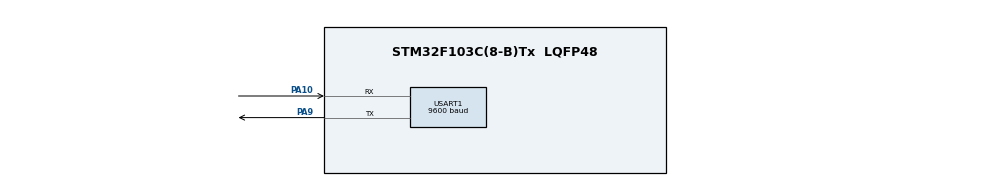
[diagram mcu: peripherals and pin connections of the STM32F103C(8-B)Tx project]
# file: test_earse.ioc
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Dma.Request0=USART1_RX
Dma.USART1_RX.0.Direction=DMA_PERIPH_TO_MEMORY
Dma.USART1_RX.0.Instance=DMA1_Channel5
Dma.USART1_RX.0.MemDataAlignment=DMA_MDATAALIGN_BYTE
Dma.USART1_RX.0.MemInc=DMA_MINC_ENABLE
Dma.USART1_RX.0.Mode=DMA_CIRCULAR
Dma.USART1_RX.0.PeriphDataAlignment=DMA_PDATAALIGN_BYTE
Dma.USART1_RX.0.PeriphInc=DMA_PINC_DISABLE
Dma.USART1_RX.0.Priority=DMA_PRIORITY_LOW
Mcu.Family=STM32F1
Mcu.Name=STM32F103C(8-B)Tx
Mcu.Package=LQFP48
NVIC.DMA1_Channel5_IRQn=true\:0\:0\:false\:false\:true\:false\:true
NVIC.PriorityGroup=NVIC_PRIORITYGROUP_4
PA10.Mode=Asynchronous
PA10.Signal=USART1_RX
PA13.Mode=Serial_Wire
PA13.Signal=SYS_JTMS-SWDIO
PA14.Mode=Serial_Wire
PA14.Signal=SYS_JTCK-SWCLK
PA9.Mode=Asynchronous
PA9.Signal=USART1_TX
ProjectManager.HeapSize=0x200
ProjectManager.StackSize=0x400
ProjectManager.TargetToolchain=STM32CubeIDE
RCC.APB1Freq_Value=8000000
RCC.APB2Freq_Value=8000000
USART1.BaudRate=9600
USART1.VirtualMode=VM_ASYNC
board=custom

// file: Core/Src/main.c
/* USER CODE BEGIN Header */
/**
 ******************************************************************************
 * @file           : main.c
 * @brief          : Main program body
 ******************************************************************************
 * @attention
 *
 * <h2><center>&copy; Copyright (c) 2021 STMicroelectronics.
 * All rights reserved.</center></h2>
 *
 * This software component is licensed by ST under BSD 3-Clause license,
 * the "License"; You may not use this file except in compliance with the
 * License. You may obtain a copy of the License at:
 *                        opensource.org/licenses/BSD-3-Clause
 *
 ******************************************************************************
 */
/* USER CODE END Header */
#include "main.h"

UART_HandleTypeDef huart1;
DMA_HandleTypeDef hdma_usart1_rx;

void SystemClock_Config(void);
static void MX_GPIO_Init(void);
static void MX_DMA_Init(void);
static void MX_USART1_UART_Init(void);

/* USER CODE BEGIN 0 */
void FlashErase(uint32_t address, uint8_t numSector)__attribute__((section(".run_in_ram")));
/* USER CODE END 0 */

int main(void)
{

  /* MCU Configuration--------------------------------------------------------*/

  /* Reset of all peripherals, Initializes the Flash interface and the Systick. */
  HAL_Init();

  /* Configure the system clock */
  SystemClock_Config();

  /* Initialize all configured peripherals */
  MX_GPIO_Init();
  MX_DMA_Init();
  MX_USART1_UART_Init();
  /* USER CODE BEGIN 2 */
	// COPY
	MY_EFROM_INIT();
	__HAL_RCC_USART1_CLK_ENABLE();
	__HAL_RCC_DMA1_CLK_ENABLE();
	HAL_UART_Init(&huart1);
	HAL_DMA_Init(&hdma_usart1_rx);

	//uint32_t *VTOR = 0xE000ED08;
	//*VTOR = 0x20000000;
	//memcpy(0x20000000, 0x08000000, 304);

  /* USER CODE END 2 */

  /* Infinite loop */
	while (1) {

    /* USER CODE BEGIN 3 */
		FlashErase(0x08000000,31);
		break;
	}
  /* USER CODE END 3 */
}

void SystemClock_Config(void)
{
  RCC_OscInitTypeDef RCC_OscInitStruct = {0};
  RCC_ClkInitTypeDef RCC_ClkInitStruct = {0};

  /** Initializes the RCC Oscillators according to the specified parameters
  * in the RCC_OscInitTypeDef structure.
  */
  RCC_OscInitStruct.OscillatorType = RCC_OSCILLATORTYPE_HSI;
  RCC_OscInitStruct.HSIState = RCC_HSI_ON;
  RCC_OscInitStruct.HSICalibrationValue = RCC_HSICALIBRATION_DEFAULT;
  RCC_OscInitStruct.PLL.PLLState = RCC_PLL_NONE;
  if (HAL_RCC_OscConfig(&RCC_OscInitStruct) != HAL_OK)
  {
    Error_Handler();
  }
  /** Initializes the CPU, AHB and APB buses clocks
  */
  RCC_ClkInitStruct.ClockType = RCC_CLOCKTYPE_HCLK|RCC_CLOCKTYPE_SYSCLK
                              |RCC_CLOCKTYPE_PCLK1|RCC_CLOCKTYPE_PCLK2;
  RCC_ClkInitStruct.SYSCLKSource = RCC_SYSCLKSOURCE_HSI;
  RCC_ClkInitStruct.AHBCLKDivider = RCC_SYSCLK_DIV1;
  RCC_ClkInitStruct.APB1CLKDivider = RCC_HCLK_DIV1;
  RCC_ClkInitStruct.APB2CLKDivider = RCC_HCLK_DIV1;

  if (HAL_RCC_ClockConfig(&RCC_ClkInitStruct, FLASH_LATENCY_0) != HAL_OK)
  {
    Error_Handler();
  }
}

static void MX_USART1_UART_Init(void)
{

  huart1.Instance = USART1;
  huart1.Init.BaudRate = 9600;
  huart1.Init.WordLength = UART_WORDLENGTH_8B;
  huart1.Init.StopBits = UART_STOPBITS_1;
  huart1.Init.Parity = UART_PARITY_NONE;
  huart1.Init.Mode = UART_MODE_TX_RX;
  huart1.Init.HwFlowCtl = UART_HWCONTROL_NONE;
  huart1.Init.OverSampling = UART_OVERSAMPLING_16;
  if (HAL_UART_Init(&huart1) != HAL_OK)
  {
    Error_Handler();
  }

}

static void MX_DMA_Init(void)
{

  /* DMA controller clock enable */
  __HAL_RCC_DMA1_CLK_ENABLE();

  /* DMA interrupt init */
  /* DMA1_Channel5_IRQn interrupt configuration */
  HAL_NVIC_SetPriority(DMA1_Channel5_IRQn, 0, 0);
  HAL_NVIC_EnableIRQ(DMA1_Channel5_IRQn);

}

static void MX_GPIO_Init(void)
{

  /* GPIO Ports Clock Enable */
  __HAL_RCC_GPIOA_CLK_ENABLE();

}

/* USER CODE BEGIN 4 */
void FlashErase(uint32_t address, uint8_t numSector) {
	uint32_t *FLASH_SR = (uint32_t*) 0x4002200C;
	uint32_t *FLASH_CR = (uint32_t*) 0x40022010;
	uint32_t *FLASH_AR = (uint32_t*) 0x40022014;

	if (((*FLASH_CR >> 1) & 1) != 1) {
		*FLASH_CR |= 1 << 1;		//Page Erase chosen
	}
	if ((*FLASH_CR & 1) == 1) {
		*FLASH_CR &= ~(1UL);
	}
	for (int i = 0; i < numSector; i++) {
		*FLASH_CR &= ~1UL;
		while (((*FLASH_SR) & 1) == 1)
			;
		*FLASH_AR = address + 0x400 * i;
		*FLASH_CR |= 1 << 6;		//Start

		while (((*FLASH_SR >> 5) & 1) != 1)
			;
		*FLASH_SR |= 1 << 5;
	}

	*FLASH_CR &= ~(1u << 1);

}
void MY_EFROM_INIT() {
	__HAL_RCC_FLITF_CLK_ENABLE();
	HAL_FLASH_Unlock();
}

/* USER CODE END 4 */

void Error_Handler(void)
{
	__disable_irq();
	while (1) {
	}
}

/************************ (C) COPYRIGHT STMicroelectronics *****END OF FILE****/
